# CH572SFR register map
Vendor: WCH Ltd.; Series: CH572; File version: 1.1
WCH wireless MCU CH572 Family Support, Drivers
CPU: RISC-V r0p0, little endian, no MPU, no FPU, 2 interrupt priority bits
Registers are 32-bit, read-write, reset 0x0 unless marked. A register's access mark holds for its fields unless they carry their own. Offsets are from the block's base; lines under a group give offsets from that group; [hi:lo] are bit positions; {n}, {i} and the like mark numbered series; 'fields as' and 'values as' point back to an identical list; <NAME> marks a mode.

## Memory map
0x40001000 SYS size 0x400 — System Control Register
0x40001000 RTC blocks up to offset 0x3F — Real time clock
0x40001000 System_control blocks up to offset 0x54 — System control related registers
0x40001000 CMP blocks up to offset 0x86 — Comparer
0x40001000 KEYSCAN blocks up to offset 0x7A — keys scanning
0x40001000 GPIO blocks up to offset 0xDC — General porpose intput output
0x40001000 KEYSCAN blocks up to offset 0x7A — keys scanning
0x40002400 TMR — Timer register
0x40003400 UART size 0x400
0x40003400 UART size 0x400
0x40004000 SPI size 0x400
0x40004800 I2C size 0x400
0x40005000 PWMx size 0x400
0x40008000 USBFS size 0x400
0x4000C000 BLE size 0x1400
0xE000E000 PFIC size 0x1000 — Program Fast Interrupt Controller
0xE000F000 Systick size 0x100

## Interrupts
17 GPIOA (GPIO) — GPIOA_IRQHandler
17 GPIO_A (SYS) — GPIOA_IRQHandler
19 SPI (SYS, SPI) — SPI_IRQHandler
20 BLEB (SYS, BLE) — BB_IRQHandler
21 BLEL (SYS, BLE) — LLE_IRQHandler
22 USB (SYS) — USB_IRQHandler
22 USBFS — USB_IRQHandler
24 TMR (SYS, TMR) — TMR_IRQHandler
26 UART0 (SYS) — UART0_IRQHandler
27 UART (SYS, UART) — UART_IRQHandler
28 RTC (SYS, RTC) — RTC_IRQHandler
29 CMP (SYS, CMP) — CMP_IRQHandler
30 I2C (SYS, I2C) — I2C_IRQHandler
31 PWMX (SYS) — PWMX_IRQHandler
31 PWMx — PWMX_IRQHandler
33 KEYSCAN (SYS, KEYSCAN) — KEYSCAN_IRQHandler
34 ENCODER (SYS) — ENCODER_IRQHandler
35 WDOG_BAT (SYS, System_control) — WDOG_BAT_IRQHandler

## RTC — Real time clock
Base 0x40001000
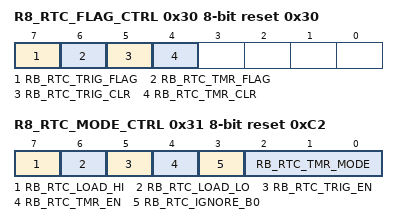
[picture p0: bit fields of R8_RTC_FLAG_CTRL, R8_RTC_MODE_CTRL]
0x30 R8_RTC_FLAG_CTRL 8-bit reset 0x30 — RWA, Real time clock
  [7] RB_RTC_TRIG_FLAG ro — RO, RTC trigger action flag
  [6] RB_RTC_TMR_FLAG ro — RO, RTC timer action flag
  [5] RB_RTC_TRIG_CLR — RW, set 1 to clear RTC trigger action flag, auto clear
  [4] RB_RTC_TMR_CLR — RW, set 1 to clear RTC timer action flag, auto clear
0x31 R8_RTC_MODE_CTRL 8-bit reset 0xC2 — RWA, RTC mode control, SAM
  [7] RB_RTC_LOAD_HI — RWA, set 1 to load RTC count high word R32_RTC_CNT_DAY, auto clear after loaded
  [6] RB_RTC_LOAD_LO — RWA, set 1 to load RTC count low word R32_RTC_CNT_32K, auto clear after loaded
  [5] RB_RTC_TRIG_EN — RWA, RTC trigger mode enable
  [4] RB_RTC_TMR_EN — RWA, RTC timer mode enable
  [3] RB_RTC_IGNORE_B0 — RWA, force ignore bit0 for trigger mode: 0=compare bit0, 1=ignore bit0
  [2:0] RB_RTC_TMR_MODE — RWA, RTC timer mode: 000=0.125S, 001=0.25S, 010=0.5S, 011=1S, 100=2S, 101=4S, 110=8S, 111=16S
0x34 R32_RTC_TRIG — RWA, RTC trigger value, SAM
  [31:0] R32_RTC_TRIG — RWA, RTC trigger value
0x38 R16_RTC_CNT_LSI 16-bit ro reset not defined — RO, RTC count based lsi
  [15:0] R16_RTC_CNT_LSI — R0,RTC count based lsi
0x3A R16_RTC_CNT_DIV1 16-bit ro reset not defined — RO, RTC count based 65536 LSI clock cycles
0x3C R32_RTC_CNT_DIV2 ro reset not defined — RO, RTC count based 2831155200 LSI clock cycles, only low 14 bit
  [13:0] R32_RTC_CNT_DIV2 — RWA,RTC count based 2831155200 LSI clock cycles

## CMP — Comparer
Base 0x40001000
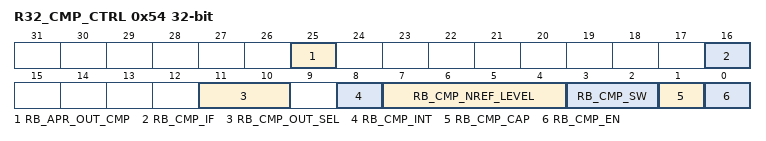
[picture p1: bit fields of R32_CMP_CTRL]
0x54 R32_CMP_CTRL — RW, Comparator control register
  [25] RB_APR_OUT_CMP — RW, Real time output signal of comparator
  [16] RB_CMP_IF — RW1, Comparator interrupt flag, write 1 to reset to zero
  [11:10] RB_CMP_OUT_SEL ro — RW, Comparator interrupt generates event selection
  [8] RB_CMP_INT — RW, Comparator interrupt enable
  [7:4] RB_CMP_NREF_LEVEL — RW, Selection of negative reference level for comparator
  [3:2] RB_CMP_SW — RW, Comparator channel selection
  [1] RB_CMP_CAP — RW, Timer captures channel signal source selection
  [0] RB_CMP_EN — RW, Comparator enabled
